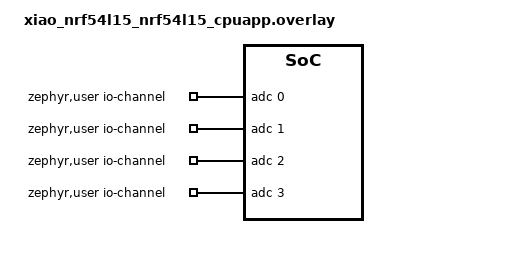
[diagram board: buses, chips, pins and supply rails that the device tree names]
/ {
	zephyr,user {
		io-channels = <&adc 0>, <&adc 1>, <&adc 2>, <&adc 3>;
	};
};

/* Disable PWM20 to release P1.04 (D0) for ADC use */
&pwm20 {
	status = "disabled";
};

&pinctrl {
	/delete-node/ pwm20_default;
	/delete-node/ pwm20_sleep;
};
